# ATSAMD20E15BU register map
Vendor: Microchip Technology Inc.; Series: SAMD20; File version: G
CPU: CM0+ r0p1, little endian, no MPU, no FPU, VTOR, 2 interrupt priority bits, 25 interrupts
Registers are 8-bit, read-write, reset 0x0 unless marked. A register's access mark holds for its fields unless they carry their own. Offsets are from the block's base; [hi:lo] are bit positions; {n}, {i} and the like mark numbered series; 'fields as' and 'values as' point back to an identical list.

## EIC — External Interrupt Controller
Base 0x40001800; register names take the prefix EIC_
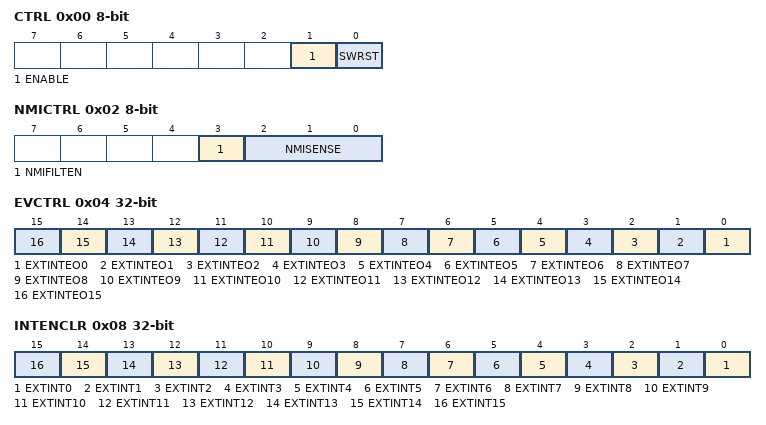
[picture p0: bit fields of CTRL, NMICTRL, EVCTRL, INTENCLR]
0x00 CTRL — Control
  [1] ENABLE
  [0] SWRST — Software Reset
0x01 STATUS ro
  [7] SYNCBUSY — Synchronization Busy
0x02 NMICTRL — Non-Maskable Interrupt Control
  [3] NMIFILTEN — Non-Maskable Interrupt Filter Enable
  [2:0] NMISENSE — Non-Maskable Interrupt Sense
    0=NONE (No detection); 1=RISE (Rising-edge detection); 2=FALL (Falling-edge detection); 3=BOTH (Both-edges detection); 4=HIGH (High-level detection); 5=LOW (Low-level detection)
0x03 NMIFLAG — Non-Maskable Interrupt Flag Status and Clear
  [0] NMI — Non-Maskable Interrupt
0x04 EVCTRL 32-bit — Event Control
  [n] EXTINTEO{n} (n=0..15) — External Interrupt {n} Event Output Enable
0x08 INTENCLR 32-bit — Interrupt Enable Clear
  [n] EXTINT{n} (n=0..15) — External Interrupt {n} Enable
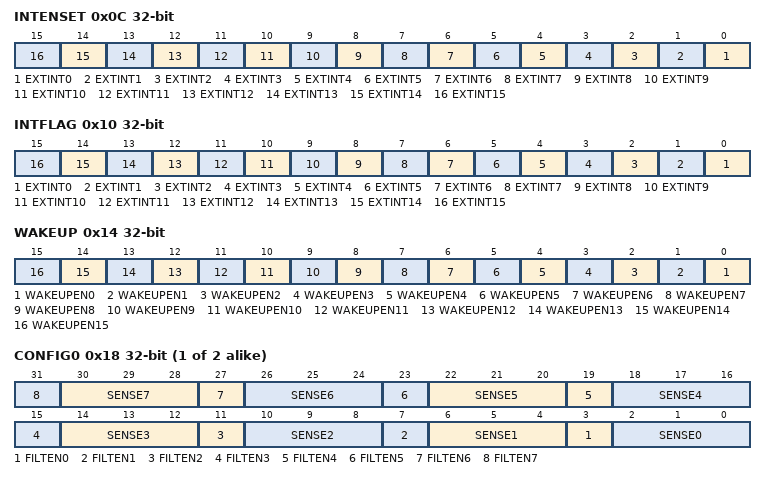
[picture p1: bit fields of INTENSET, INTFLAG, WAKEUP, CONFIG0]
0x0C INTENSET 32-bit — Interrupt Enable Set
  [n] EXTINT{n} (n=0..15) — External Interrupt {n} Enable
0x10 INTFLAG 32-bit — Interrupt Flag Status and Clear
  [n] EXTINT{n} (n=0..15) — External Interrupt {n}
0x14 WAKEUP 32-bit — Wake-Up Enable
  [n] WAKEUPEN{n} (n=0..15) — External Interrupt {n} Wake-up Enable
{0x18+4i} CONFIG{i} (i=0..1) 32-bit — Configuration n
  [4n+3] FILTEN{n} (n=0..7) — Filter {n} Enable
  [4n+2:4n] SENSE{n} (n=1..7) — Input Sense {n} Configuration
    0=NONE (No detection); 1=RISE (Rising edge detection); 2=FALL (Falling edge detection); 3=BOTH (Both edges detection); 4=HIGH (High level detection); 5=LOW (Low level detection)
  [2:0] SENSE0 — Input Sense 0 Configuration
    values as NMICTRL.NMISENSE

## EVSYS — Event System Interface
Base 0x42000400; register names take the prefix EVSYS_
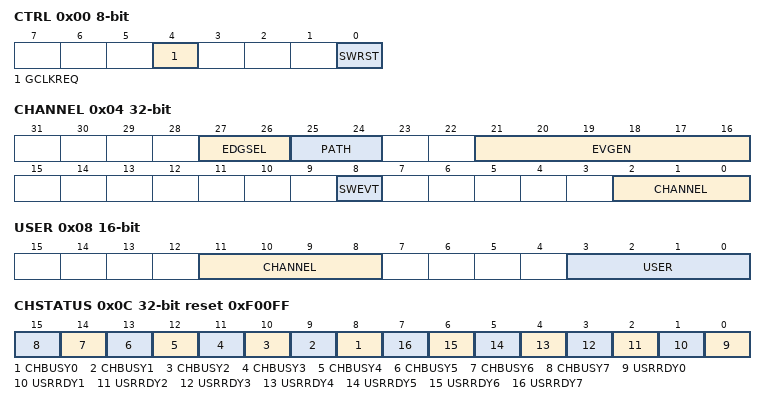
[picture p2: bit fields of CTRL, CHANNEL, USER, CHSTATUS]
0x00 CTRL wo — Control
  [4] GCLKREQ — Generic Clock Requests
  [0] SWRST — Software Reset
0x04 CHANNEL 32-bit
  [27:26] EDGSEL — Edge Detection Selection
    0=NO_EVT_OUTPUT (No event output when using the resynchronized or synchronous path); 1=RISING_EDGE (Event detection only on the rising edge of the signal from the event generator when using the resynchronized or synchronous path); 2=FALLING_EDGE (Event detection only on the falling edge of the signal from the event generator when using the resynchronized or synchronous path); 3=BOTH_EDGES (Event detection on rising and falling edges of the signal from the event generator when using the resynchronized or synchronous path)
  [25:24] PATH — Path Selection
    0=SYNCHRONOUS (Synchronous path); 1=RESYNCHRONIZED (Resynchronized path); 2=ASYNCHRONOUS (Asynchronous path)
  [21:16] EVGEN — Event Generator Selection
  [8] SWEVT — Software Event
  [2:0] CHANNEL — Channel Selection
0x08 USER 16-bit — User Multiplexer
  [11:8] CHANNEL — Channel Event Selection
    0=No Channel Output Selected
  [3:0] USER — User Multiplexer Selection
0x0C CHSTATUS 32-bit ro reset 0xF00FF — Channel Status
  [n+8] CHBUSY{n} (n=0..7) — Channel {n} Busy
  [n] USRRDY{n} (n=0..7) — Channel {n} User Ready
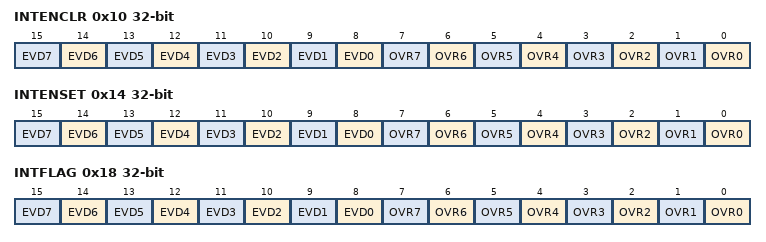
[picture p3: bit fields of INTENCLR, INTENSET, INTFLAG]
0x10 INTENCLR 32-bit — Interrupt Enable Clear
  [n+8] EVD{n} (n=0..7) — Channel {n} Event Detection Interrupt Enable
  [n] OVR{n} (n=0..7) — Channel {n} Overrun Interrupt Enable
0x14 INTENSET 32-bit — Interrupt Enable Set
  fields as INTENCLR
0x18 INTFLAG 32-bit — Interrupt Flag Status and Clear
  [n+8] EVD{n} (n=0..7) — Channel {n} Event Detection
  [n] OVR{n} (n=0..7) — Channel {n} Overrun

## GCLK — Generic Clock Generator
Base 0x40000C00; register names take the prefix GCLK_
0x00 CTRL — Control
  [0] SWRST — Software Reset
0x01 STATUS ro
  [7] SYNCBUSY — Synchronization Busy Status
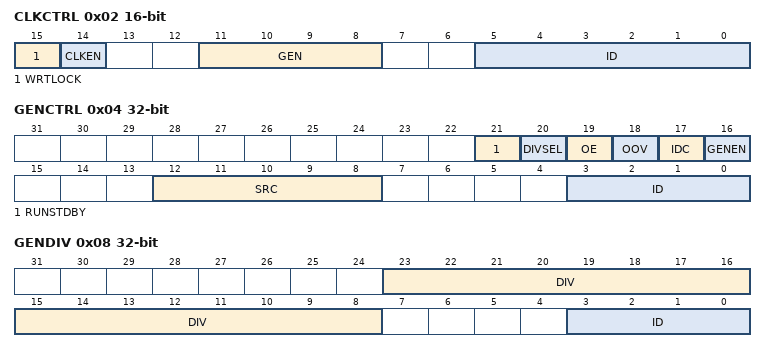
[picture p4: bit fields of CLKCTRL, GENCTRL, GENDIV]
0x02 CLKCTRL 16-bit — Generic Clock Control
  [15] WRTLOCK — Write Lock
  [14] CLKEN — Clock Enable
  [11:8] GEN — Generic Clock Generator
    {v}=GCLK{v} (Generic clock generator {v}) (v=0..7)
  [5:0] ID — Generic Clock Selection ID
    0=DFLL48M (DFLL48M Reference); 1=WDT; 2=RTC; 3=EIC; {v}=EVSYS_CHANNEL_{v-4} (v=4..11); 12=SERCOMX_SLOW; {v}=SERCOM{v-13}_CORE (v=13..18); 19=TC0_TC1; 20=TC2_TC3; 21=TC4_TC5; 22=TC6_TC7; 23=ADC; 24=AC_DIG; 25=AC_ANA; 26=DAC
0x04 GENCTRL 32-bit — Generic Clock Generator Control
  [21] RUNSTDBY — Run in Standby
  [20] DIVSEL — Divide Selection
    0=DIV1 (Divide input directly by divider factor); 1=DIV2 (Divide input by 2^(divider factor + 1))
  [19] OE — Output Enable
  [18] OOV — Output Off Value
  [17] IDC — Improve Duty Cycle
  [16] GENEN — Generic Clock Generator Enable
  [12:8] SRC — Source Select
    0=XOSC (XOSC oscillator output); 1=GCLKIN (Generator input pad); 2=GCLKGEN1 (Generic clock generator 1 output); 3=OSCULP32K (OSCULP32K oscillator output); 4=OSC32K (OSC32K oscillator output); 5=XOSC32K (XOSC32K oscillator output); 6=OSC8M (OSC8M oscillator output); 7=DFLL48M (DFLL48M output)
  [3:0] ID — Generic Clock Generator Selection
    {v}=GCLK{v} (Generic clock generator {v}) (v=0..7)
0x08 GENDIV 32-bit — Generic Clock Generator Division
  [23:8] DIV — Division Factor
  [3:0] ID — Generic Clock Generator Selection
    {v}=GCLK{v} (Generic clock generator {v}) (v=0..7)
